# AT32UC3C0256C device description
Architecture: AVR32_UC3; Family: AVR UC3
Registers are 32-bit, read-write, reset 0x0 unless marked. A register's access mark holds for its fields unless they carry their own. Offsets are from the block's base; [hi:lo] are bit positions; {n}, {i} and the like mark numbered series.

## PEVC — Peripheral Event Controller
Instances: PEVC 0xffff5c00
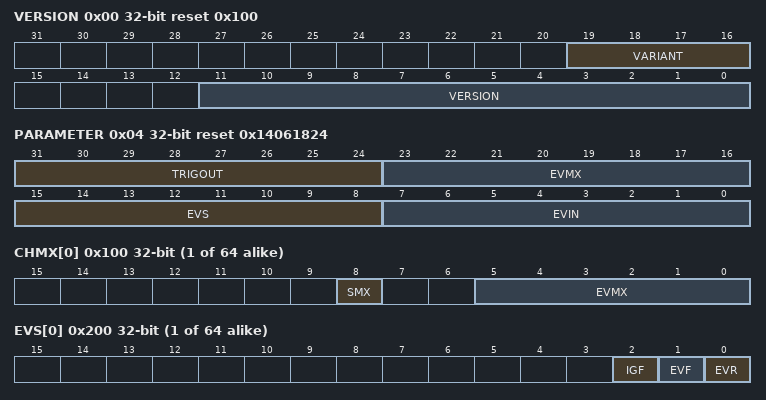
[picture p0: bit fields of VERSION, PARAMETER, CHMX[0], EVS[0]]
0x00 VERSION ro reset 0x100 — PEVC Version Register
  [19:16] VARIANT, [11:0] VERSION
0x04 PARAMETER ro reset 0x14061824 — PEVC Parameter Register
  [31:24] TRIGOUT — Number of Trigger Outputs/Users
  [23:16] EVMX — Number of Bits to Control Event Multiplexers
  [15:8] EVS — Number of Event Shaper Inputs
  [7:0] EVIN — Number of Event Inputs/Generators
0x08 IGFDR — Input Glitch Filter Divider Register
  [3:0] IGFDR
0x10 CHSR0 ro — Channel Status Register (bits 31:0)
  [31:0] CHSR — Channel Status Bits 31:0
0x14 CHSR1 ro — Channel Status Register (bits 63:32)
  [31:0] CHSR — Channel Status Bits 63:32
0x20 CHER0 wo — Channel Enable Register (bits 31:0)
  [31:0] CHER — Channel Enable Bits 31:0
0x24 CHER1 wo — Channel Enable Register (bits 63:32)
  [31:0] CHER — Channel Enable Bits 63:32
0x30 CHDR0 wo — Channel Disable Register (bits 31:0)
  [31:0] CHDR — Channel Disable Bits 31:0
0x34 CHDR1 wo — Channel Disable Register (bits 63:32)
  [31:0] CHDR — Channel Disable Bits 63:32
0x40 SEV0 wo — Software Event Register (bits 31:0)
  [31:0] SEV — Software Event Bits 31:0
0x44 SEV1 wo — Software Event Register (bits 63:32)
  [31:0] SEV — Software Event Bits 63:32
0x50 BUSY0 ro — Channel/User Busy Register (bits 31:0)
  [31:0] BUSY — Channel/User Busy Bits 31:0
0x54 BUSY1 ro — Channel/User Busy Register (bits 63:32)
  [31:0] BUSY — Channel/User Busy Bits 63:32
0x60 TRSR0 ro — Trigger Status Register (bits 31:0)
  [31:0] TRSR — Trigger Status Bits 31:0
0x64 TRSR1 ro — Trigger Status Register (bits 63:32)
  [31:0] TRSR — Trigger Status Bits 63:32
0x70 TRSCR0 wo — Trigger Status Clear Register (bits 31:0)
  [31:0] TRSCR — Trigger Status Clear Bits 31:0
0x74 TRSCR1 wo — Trigger Status Clear Register (bits 63:32)
  [31:0] TRSCR — Trigger Status Clear Bits 63:32
0x80 TRIMR0 ro — Trigger Interrupt Mask Register (bits 31:0)
  [31:0] TRIMR — Trigger Interrupt Mask Bits 31:0
0x84 TRIMR1 ro — Trigger Interrupt Mask Register (bits 63:32)
  [31:0] TRIMR — Trigger Interrupt Mask Bits 63:32
0x90 TRIER0 wo — Trigger Interrupt Enable Register (bits 31:0)
  [31:0] TRIER — Trigger Interrupt Enable Bits 31:0
0x94 TRIER1 wo — Trigger Interrupt Enable Register (bits 63:32)
  [31:0] TRIER — Trigger Interrupt Enable Bits 63:32
0xA0 TRIDR0 wo — Trigger Interrupt Disable Register (bits 31:0)
  [31:0] TRIDR — Trigger Interrupt Disable Bits 31:0
0xA4 TRIDR1 wo — Trigger Interrupt Disable Register (bits 63:32)
  [31:0] TRIDR — Trigger Interrupt Disable Bits 63:32
0xB0 OVSR0 ro — Overrun Status Register (bits 31:0)
  [31:0] OVSR — Overrun Status Bits 31:0
0xB4 OVSR1 ro — Overrun Status Register (bits 63:32)
  [31:0] OVSR — Overrun Status Bits 63:32
0xC0 OVSCR0 wo — Overrun Status Clear Register (bits 31:0)
  [31:0] OVSCR — Overrun Status Clear Bits 31:0
0xC4 OVSCR1 wo — Overrun Status Clear Register (bits 63:32)
  [31:0] OVSCR — Overrun Status Clear Bits 63:32
0xD0 OVIMR0 ro — Overrun Interrupt Mask Register (bits 31:0)
  [31:0] OVIMR — Overrun Interrupt Mask Bits 31:0
0xD4 OVIMR1 ro — Overrun Interrupt Mask Register (bits 63:32)
  [31:0] OVIMR — Overrun Interrupt Mask Bits 63:32
0xE0 OVIER0 wo — Overrun Interrupt Enable Register (bits 31:0)
  [31:0] OVIER — Overrun Interrupt Enable Bits 31:0
0xE4 OVIER1 wo — Overrun Interrupt Enable Register (bits 63:32)
  [31:0] OVIER — Overrun Interrupt Enable Bits 63:32
0xF0 OVIDR0 wo — Overrun Interrupt Disable Register (bits 31:0)
  [31:0] OVIDR — Overrun Interrupt Disable Bits 31:0
0xF4 OVIDR1 wo — Overrun Interrupt Disable Register (bits 63:32)
  [31:0] OVIDR — Overrun Interrupt Disable Bits 63:32
{0x100+4i} CHMX[{i}] (i=0..63) access not given
  [8] SMX — Software Event Multiplexer Select for channel j
  [5:0] EVMX — Event Multiplexer Select for channel j
{0x200+4i} EVS[{i}] (i=0..63) access not given
  [2] IGF — Input Glitch Filter
  [1] EVF — Event Fall
  [0] EVR — Event Rise
